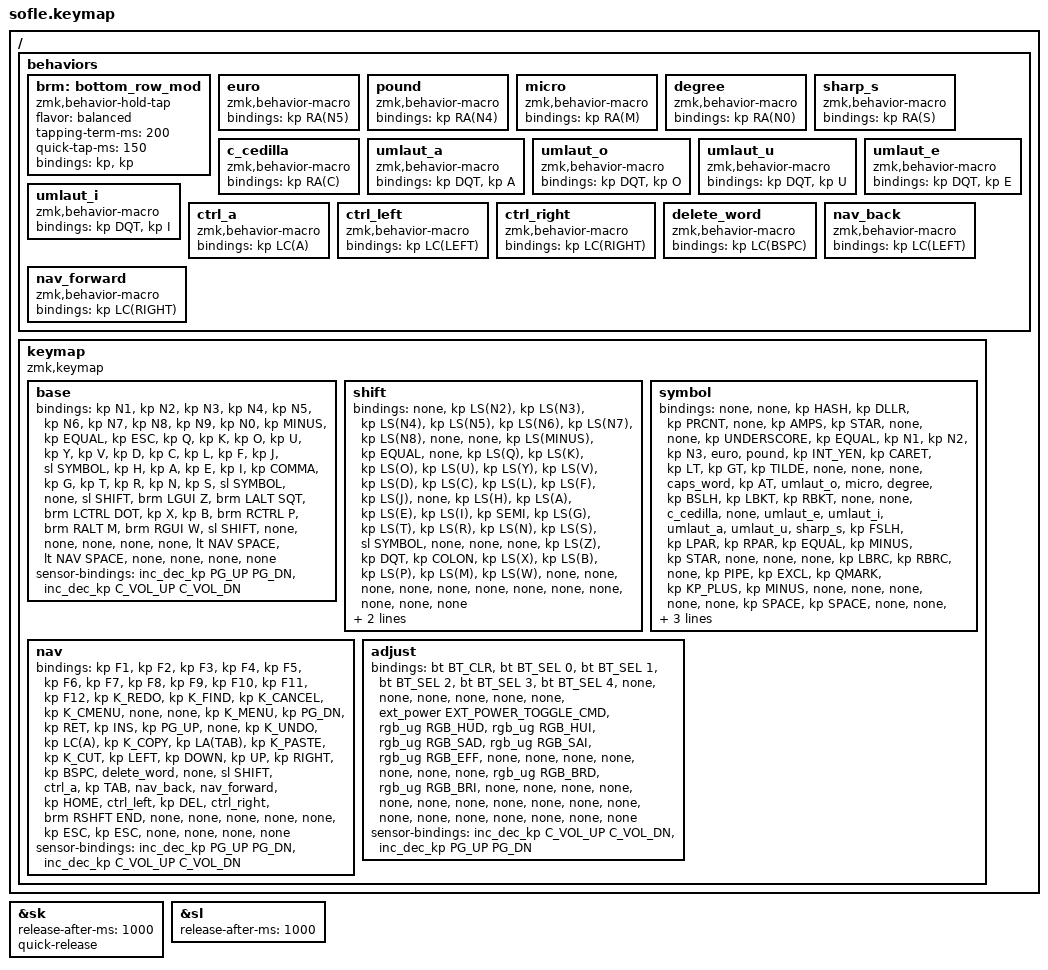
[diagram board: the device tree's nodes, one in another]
/*
* Anymak:END for Sofle Choc v2.1 (or at least that's what I use)
* Based on https://kbd.news/END-my-final-keyboard-layout2609.html
*
* Layers
*   0 BASE
*   1 SHIFT
*   2 SYMBOL
*   3 NAV
*   4 ADJUST
*
* Features
*   - END alpha layout
*   - one-shot shift
*   - one-shot Symbol
*   - bottom-row Ctrl/Alt/Super
*   - SpaceFN Nav
*/

#include <behaviors.dtsi>
#include <dt-bindings/zmk/keys.h>
#include <dt-bindings/zmk/bt.h>
#include <dt-bindings/zmk/rgb.h>
#include <dt-bindings/zmk/ext_power.h>

#define BASE 0
#define SHIFT 1
#define SYMBOL 2
#define NAV 3
#define ADJUST 4

/ {
    behaviors {
        brm: bottom_row_mod {
            compatible = "zmk,behavior-hold-tap";
            #binding-cells = <2>;
            flavor = "balanced";
            tapping-term-ms = <200>;
            quick-tap-ms = <150>;
            bindings = <&kp>, <&kp>;
        };

        /*
        * Us-International special chars
        */
        euro: euro {
            compatible = "zmk,behavior-macro";
            #binding-cells = <0>;
            bindings = <&kp RA(N5)>;
        };

        pound: pound {
            compatible = "zmk,behavior-macro";
            #binding-cells = <0>;
            bindings = <&kp RA(N4)>;
        };

        micro: micro {
            compatible = "zmk,behavior-macro";
            #binding-cells = <0>;
            bindings = <&kp RA(M)>;
        };

        degree: degree {
            compatible = "zmk,behavior-macro";
            #binding-cells = <0>;
            bindings = <&kp RA(N0)>;
        };

        sharp_s: sharp_s {
            compatible = "zmk,behavior-macro";
            #binding-cells = <0>;
            bindings = <&kp RA(S)>;
        };

        c_cedilla: c_cedilla {
            compatible = "zmk,behavior-macro";
            #binding-cells = <0>;
            bindings = <&kp RA(C)>;
        };

        /*
        * US-International dead-key combs
        */
        umlaut_a: umlaut_a {
            compatible = "zmk,behavior-macro";
            #binding-cells = <0>;
            bindings = <&kp DQT &kp A>;
        };

        umlaut_o: umlaut_o {
            compatible = "zmk,behavior-macro";
            #binding-cells = <0>;
            bindings = <&kp DQT &kp O>;
        };

        umlaut_u: umlaut_u {
            compatible = "zmk,behavior-macro";
            #binding-cells = <0>;
            bindings = <&kp DQT &kp U>;
        };

        umlaut_e: umlaut_e {
            compatible = "zmk,behavior-macro";
            #binding-cells = <0>;
            bindings = <&kp DQT &kp E>;
        };

        umlaut_i: umlaut_i {
            compatible = "zmk,behavior-macro";
            #binding-cells = <0>;
            bindings = <&kp DQT &kp I>;
        };

        /*
        * Navigation
        */
        ctrl_a: ctrl_a {
            compatible = "zmk,behavior-macro";
            #binding-cells = <0>;
            bindings = <&kp LC(A)>;
        };

        ctrl_left: ctrl_left {
            compatible = "zmk,behavior-macro";
            #binding-cells = <0>;
            bindings = <&kp LC(LEFT)>;
        };

        ctrl_right: ctrl_right {
            compatible = "zmk,behavior-macro";
            #binding-cells = <0>;
            bindings = <&kp LC(RIGHT)>;
        };

        delete_word: delete_word {
            compatible = "zmk,behavior-macro";
            #binding-cells = <0>;
            bindings = <&kp LC(BSPC)>;
        };

        nav_back: nav_back {
            compatible = "zmk,behavior-macro";
            #binding-cells = <0>;
            bindings = <&kp LC(LEFT)>;
        };

        nav_forward: nav_forward {
            compatible = "zmk,behavior-macro";
            #binding-cells = <0>;
            bindings = <&kp LC(RIGHT)>;
        };
    };
};

&sk {
    release-after-ms = <1000>;
    quick-release;
};

&sl {
    release-after-ms = <1000>;
};

// Activate ADJUST layer only when we add a key for it
/* conditional_layers { */
    /*     compatible = "zmk,conditional-layers"; */
    /*     adjust_layer { */
        /*         if-layers = <LOWER RAISE>; */
        /*         then-layer = <ADJUST>; */
    /*     }; */
/* }; */
/ {
    keymap {
        compatible = "zmk,keymap";

        // ==== //
        // BASE //
        // ==== //
        base {
            bindings = <
            // +----------------------------------------------------+
            // | Number row                                         |
            // +----------------------------------------------------+
            // | 1 | 2 | 3 | 4 | 5 | 6 |    | 7 | 8 | 9 | 0 | - | + |
            // +----------------------------------------------------+
            &kp N1 &kp N2 &kp N3 &kp N4 &kp N5 &kp N6
            &kp N7 &kp N8 &kp N9 &kp N0 &kp MINUS &kp EQUAL

            // +------------------------------------------------------+
            // | Top row                                              |
            // +------------------------------------------------------+
            // | ESC | q | k | o | u | y |    | v | d | c | l | f | j |
            // +------------------------------------------------------+
            &kp ESC &kp Q &kp K &kp O &kp U &kp Y
            &kp V &kp D &kp C &kp L &kp F &kp J

            // +--------------------------------------------------------+
            // | Home row                                               |
            // +--------------------------------------------------------+
            // | SYM | h | a | e | i | , |    | g | t | r | n | s | SYM |
            // +--------------------------------------------------------+
            &sl SYMBOL &kp H &kp A &kp E &kp I &kp COMMA
            &kp G &kp T &kp R &kp N &kp S &sl SYMBOL

            // +----------------------------------------------------------------------------------------------------+
            // | Bot row                                                                                            |
            // +----------------------------------------------------------------------------------------------------+
            // |    | SHIFT | z / GUI | ' / ALT | . / CTRL | x |    | b | p / CTRL | m / ALT | w / GUI | SHIFT |    |
            // +----------------------------------------------------------------------------------------------------+
            &none &sl SHIFT &brm LGUI Z &brm LALT SQT &brm LCTRL DOT &kp X
            &kp B &brm RCTRL P &brm RALT M &brm RGUI W &sl SHIFT &none

            // +------------------------------------------------------------+
            // | Thumb keys                                                 |
            // +------------------------------------------------------------+
            // |    |    |    |    | SPACE |    | SPACE |    |    |    |    |
            // +------------------------------------------------------------+
            &none &none &none &none &lt NAV SPACE
            &lt NAV SPACE &none &none &none &none
            >;

            sensor-bindings = <&inc_dec_kp PG_UP PG_DN &inc_dec_kp C_VOL_UP C_VOL_DN>;
        };

        // ===== //
        // SHIFT //
        // ===== //
        // oneshit
        shift {
            bindings = <
            // +-----------------------------------------------------+
            // | Number row                                          |
            // +-----------------------------------------------------+
            // |    | @ | # | $ | % | ^ |    | & | * | ( | ) | _ | = |
            // +-----------------------------------------------------+
            &none &kp LS(N2) &kp LS(N3) &kp LS(N4) &kp LS(N5) &kp LS(N6)
            &kp LS(N7) &kp LS(N8) &none &none &kp LS(MINUS) &kp EQUAL

            // +-----------------------------------------------------+
            // | Top row                                             |
            // +-----------------------------------------------------+
            // |    | Q | K | O | U | Y |    | V | D | C | L | F | J |
            // +-----------------------------------------------------+
            &none &kp LS(Q) &kp LS(K) &kp LS(O) &kp LS(U) &kp LS(Y)
            &kp LS(V) &kp LS(D) &kp LS(C) &kp LS(L) &kp LS(F) &kp LS(J)

            // +--------------------------------------------------------+
            // | Home row                                               |
            // +--------------------------------------------------------+
            // | SYM | H | A | E | I | ; |    | G | T | R | N | S | SYM |
            // +--------------------------------------------------------+
            &none &kp LS(H) &kp LS(A) &kp LS(E) &kp LS(I) &kp SEMI
            &kp LS(G) &kp LS(T) &kp LS(R) &kp LS(N) &kp LS(S) &sl SYMBOL &none

            // +--------------------------------------------------------+
            // | Bot row                                                |
            // +--------------------------------------------------------+
            // |    |    | Z | " | : | X |    | B | P | M | W |    |    |
            // +--------------------------------------------------------+
            &none &none &kp LS(Z) &kp DQT &kp COLON &kp LS(X)
            &kp LS(B) &kp LS(P) &kp LS(M) &kp LS(W) &none &none

            // +------------------------------------------------------+
            // | Thumb keys                                           |
            // +------------------------------------------------------+
            // |    |    |    |    |    |    |    |    |    |    |    |
            // +------------------------------------------------------+
            &none &none &none &none &none
            &none &none &none &none &none
            >;

            sensor-bindings = <&inc_dec_kp PG_UP PG_DN &inc_dec_kp C_VOL_UP C_VOL_DN>;
        };

        // ====== //
        // SYMBOL //
        // ====== //
        // oneshit
        symbol {
            bindings = <
            // +---------------------------------------------------------+
            // | Number row (shift-layer)                                |
            // +---------------------------------------------------------+
            // |    |    | # | $ | % | ^d |    | & | * |    |    | _ | = |
            // +---------------------------------------------------------+
            &none &none &kp HASH &kp DLLR &kp PRCNT &none
            &kp AMPS &kp STAR &none &none &kp UNDERSCORE &kp EQUAL

            // +---------------------------------------------------------+
            // | Number row                                              |
            // +---------------------------------------------------------+
            // | ^1 | ^2 | ^3 | € | £ | ¥ |    | ^ | < | > | ~ | ~d |    |
            // +---------------------------------------------------------+
            &kp N1 &kp N2 &kp N3 &euro &pound &kp INT_YEN
            &kp CARET &kp LT &kp GT &kp TILDE &none &none

            // +-----------------------------------------------------------------+
            // | Top row                                                         |
            // +-----------------------------------------------------------------+
            // |    | CAPS_WORD | @ | o: | μ | ° |    | \ | [ | ] | 'd | d` | c, |
            // +-----------------------------------------------------------------+
            &none &caps_word &kp AT &umlaut_o &micro &degree
            &kp BSLH &kp LBKT &kp RBKT &none &none &c_cedilla

            // +---------------------------------------------------------+
            // | Home row                                                |
            // +---------------------------------------------------------+
            // |    | :e | :i | :a | :u | ß |    | / | ( | ) | = | - | * |
            // +---------------------------------------------------------+
            &none &umlaut_e &umlaut_i &umlaut_a &umlaut_u &sharp_s
            &kp FSLH &kp LPAR &kp RPAR &kp EQUAL &kp MINUS &kp STAR

            // +-----------------------------------------------------------+
            // | Bot row                                                   |
            // +-----------------------------------------------------------+
            // |    |    |    | { | } |    |    | '|' | ! | ? | + | _ |    |
            // +-----------------------------------------------------------+
            &none &none &none &kp LBRC &kp RBRC &none
            &kp PIPE &kp EXCL &kp QMARK &kp KP_PLUS &kp MINUS &none

            // +------------------------------------------------------------+
            // | Thumb keys                                                 |
            // +------------------------------------------------------------+
            // |    |    |    |    | SPACE |    | SPACE |    |    |    |    |
            // +------------------------------------------------------------+
            &none &none &none &none &kp SPACE
            &kp SPACE &none &none &none &none
            >;

            sensor-bindings = <&inc_dec_kp PG_UP PG_DN &inc_dec_kp C_VOL_UP C_VOL_DN>;
        };

        // === //
        // NAV //
        // === //
        // hold
        nav {
            bindings = <
            // +--------------------------------------------------------------+
            // | Number row                                                   |
            // +--------------------------------------------------------------+
            // | F1 | F2 | F3 | F4 | F5 | F6 | F7 | F8 | F9 | F10 | F11 | F12 |
            // +--------------------------------------------------------------+
            &kp F1 &kp F2 &kp F3 &kp F4 &kp F5 &kp F6
            &kp F7 &kp F8 &kp F9 &kp F10 &kp F11 &kp F12

            // +---------------------------------------------------------------------------------------------------+
            // | Top row                                                                                           |
            // +---------------------------------------------------------------------------------------------------+
            // | REDO | FIND | CLOSE_TAB | NEW_TAB |    |    |    | Menu | PAGE_DN | Enter | INSERT | PAGE_UP |    |
            // +---------------------------------------------------------------------------------------------------+
            &kp K_REDO &kp K_FIND &kp K_CANCEL &kp K_CMENU &none &none
            &kp K_MENU &kp PG_DN &kp RET &kp INS &kp PG_UP &none

            // +-------------------------------------------------------------------------------------------------------+
            // | Home row                                                                                              |
            // +-------------------------------------------------------------------------------------------------------+
            // | UNDO | EVERYTHING | COPY | ALT_TAB | PASTE | CUT |    | LEFT | DOWN | UP | RIGHT | BKSP | DELETE_WORD |
            // +-------------------------------------------------------------------------------------------------------+
            &kp K_UNDO &kp LC(A) &kp K_COPY &kp LA(TAB) &kp K_PASTE &kp K_CUT
            &kp LEFT &kp DOWN &kp UP &kp RIGHT &kp BSPC &delete_word

            // +-----------------------------------------------------------------------------------------------------------+
            // | Bot row                                                                                                   |
            // +-----------------------------------------------------------------------------------------------------------+
            // |    | SHIFT | CTRL_A | TAB | BACK | FORWARD |    | POS_1 | CTRL_LEFT | DEL | CTRL_RIGHT | END / SHIFT |    |
            // +-----------------------------------------------------------------------------------------------------------+
            &none &sl SHIFT &ctrl_a &kp TAB &nav_back &nav_forward
            &kp HOME &ctrl_left &kp DEL &ctrl_right &brm RSHFT END &none

            // +--------------------------------------------------------+
            // | Thumb keys                                             |
            // +--------------------------------------------------------+
            // |    |    |    |    | ESC |    | ESC |    |    |    |    |
            // +--------------------------------------------------------+
            &none &none &none &none &kp ESC
            &kp ESC &none &none &none &none
            >;

            sensor-bindings = <&inc_dec_kp PG_UP PG_DN &inc_dec_kp C_VOL_UP C_VOL_DN>;
        };

        // ====== //
        // ADJUST //
        // ====== //
        adjust {
            bindings = <
            &bt BT_CLR
            &bt BT_SEL 0
            &bt BT_SEL 1
            &bt BT_SEL 2
            &bt BT_SEL 3
            &bt BT_SEL 4

            &none &none &none &none &none &none

            &ext_power EXT_POWER_TOGGLE_CMD
            &rgb_ug RGB_HUD
            &rgb_ug RGB_HUI
            &rgb_ug RGB_SAD
            &rgb_ug RGB_SAI
            &rgb_ug RGB_EFF

            &none &none &none &none &none &none

            &none
            &rgb_ug RGB_BRD
            &rgb_ug RGB_BRI
            &none
            &none
            &none

            &none
            &none
            &none
            &none
            &none
            &none

            &none &none &none &none &none
            &none &none &none &none
            >;

            sensor-bindings =
            <&inc_dec_kp C_VOL_UP C_VOL_DN
            &inc_dec_kp PG_UP PG_DN>;
        };
    };
};
